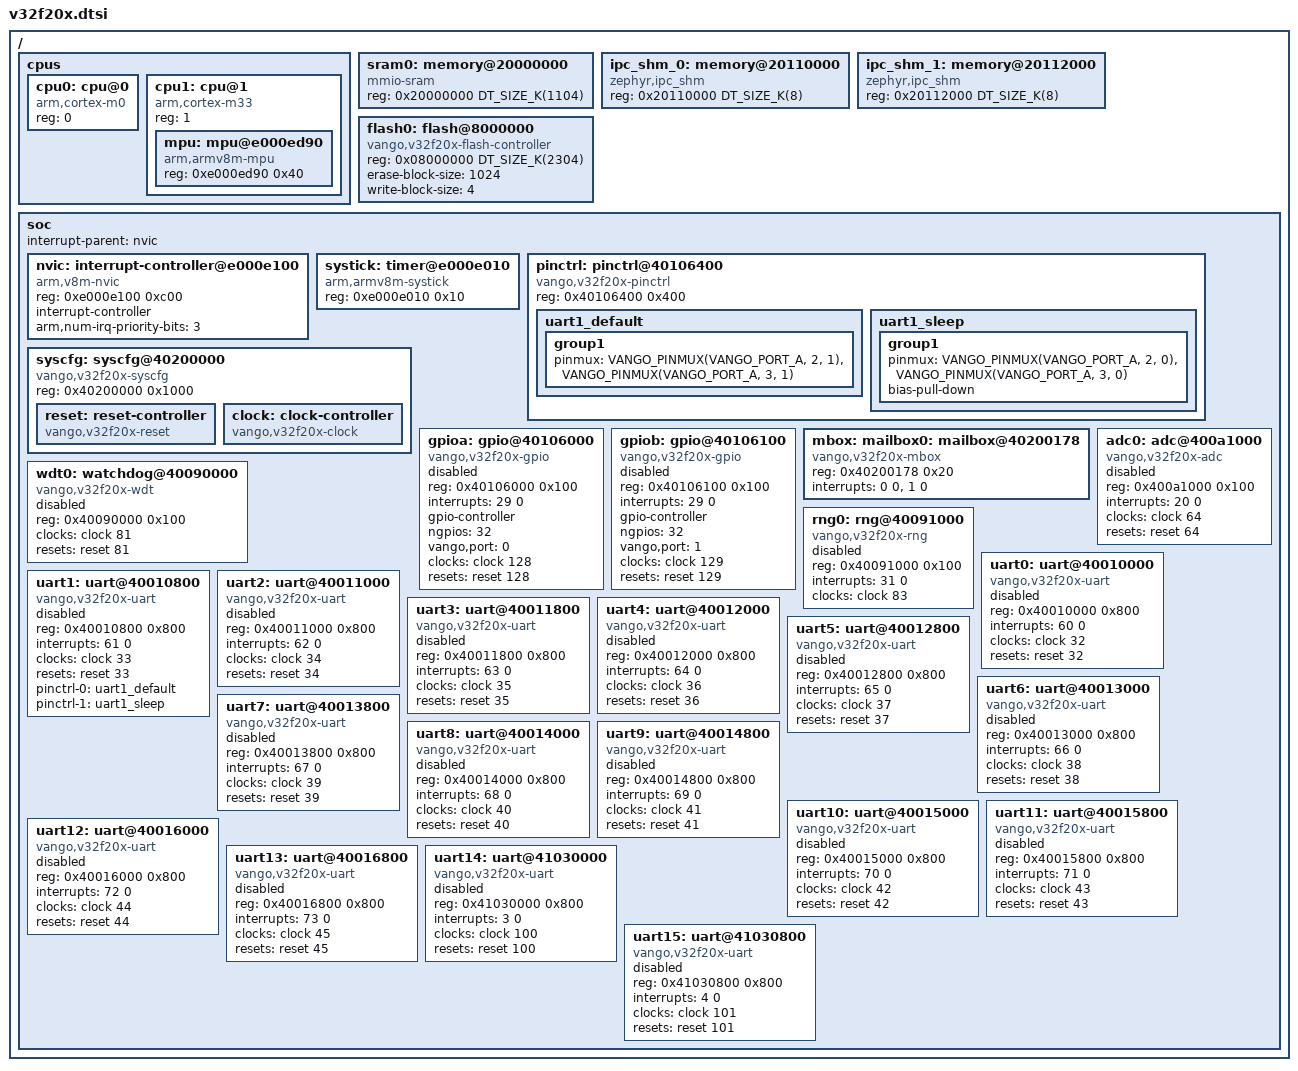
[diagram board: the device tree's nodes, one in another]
/*
 * Copyright (c) 2024 Vango Technologies
 * SPDX-License-Identifier: Apache-2.0
 */

#include <arm/armv8-m.dtsi>
#include <zephyr/dt-bindings/gpio/gpio.h>
#include <zephyr/dt-bindings/pinctrl/vango-v32f20x-pinctrl.h>
#include <mem.h>

/ {
    cpus {
        #address-cells = <1>;
        #size-cells = <0>;

        cpu0: cpu@0 {
            device_type = "cpu";
            compatible = "arm,cortex-m0";
            reg = <0>;
        };

        cpu1: cpu@1 {
            device_type = "cpu";
            compatible = "arm,cortex-m33";
            reg = <1>;
            #address-cells = <1>;
            #size-cells = <1>;

            mpu: mpu@e000ed90 {
                compatible = "arm,armv8m-mpu";
                reg = <0xe000ed90 0x40>;
            };
        };
    };

    sram0: memory@20000000 {
        compatible = "mmio-sram";
        reg = <0x20000000 DT_SIZE_K(1104)>;
    };

    ipc_shm_0: memory@20110000 {
        compatible = "zephyr,ipc_shm";
        reg = <0x20110000 DT_SIZE_K(8)>;
    };

    ipc_shm_1: memory@20112000 {
        compatible = "zephyr,ipc_shm";
        reg = <0x20112000 DT_SIZE_K(8)>;
    };

    flash0: flash@8000000 {
        compatible = "vango,v32f20x-flash-controller";
        reg = <0x08000000 DT_SIZE_K(2304)>;
        erase-block-size = <1024>;
        write-block-size = <4>;
    };

    soc: soc {
        #address-cells = <1>;
        #size-cells = <1>;
        ranges;
        interrupt-parent = <&nvic>;

        nvic: interrupt-controller@e000e100 {
            compatible = "arm,v8m-nvic";
            reg = <0xe000e100 0xc00>;
            interrupt-controller;
            #interrupt-cells = <2>;
            arm,num-irq-priority-bits = <3>;
        };

        systick: timer@e000e010 {
            status = "okay";
            compatible = "arm,armv8m-systick";
            reg = <0xe000e010 0x10>;
        };

        pinctrl: pinctrl@40106400 {
            compatible = "vango,v32f20x-pinctrl";
            reg = <0x40106400 0x400>;

            uart1_default: uart1_default {
                group1 {
                    pinmux = <VANGO_PINMUX(VANGO_PORT_A, 2, 1)>,
                             <VANGO_PINMUX(VANGO_PORT_A, 3, 1)>;
                };
            };
            uart1_sleep: uart1_sleep {
                group1 {
                    pinmux = <VANGO_PINMUX(VANGO_PORT_A, 2, 0)>,
                             <VANGO_PINMUX(VANGO_PORT_A, 3, 0)>;
                    bias-pull-down;
                };
            };
        };

        syscfg: syscfg@40200000 {
            compatible = "vango,v32f20x-syscfg", "syscon";
            reg = <0x40200000 0x1000>;

            reset: reset-controller {
                compatible = "vango,v32f20x-reset";
                #reset-cells = <1>;
            };

            clock: clock-controller {
                compatible = "vango,v32f20x-clock";
                #clock-cells = <1>;
            };
        };

        gpioa: gpio@40106000 {
            compatible = "vango,v32f20x-gpio";
            reg = <0x40106000 0x100>;
            interrupts = <29 0>;
            gpio-controller;
            #gpio-cells = <2>;
            ngpios = <32>;
            vango,port = <0>;
            clocks = <&clock 128>;
            resets = <&reset 128>;
            status = "disabled";
        };

        gpiob: gpio@40106100 {
            compatible = "vango,v32f20x-gpio";
            reg = <0x40106100 0x100>;
            interrupts = <29 0>;
            gpio-controller;
            #gpio-cells = <2>;
            ngpios = <32>;
            vango,port = <1>;
            clocks = <&clock 129>;
            resets = <&reset 129>;
            status = "disabled";
        };

        mbox: mailbox0: mailbox@40200178 {
            compatible = "vango,v32f20x-mbox";
            reg = <0x40200178 0x20>;
            interrupts = <0 0>, <1 0>;
            #mbox-cells = <1>;
            status = "okay";
        };

        wdt0: watchdog@40090000 {
            compatible = "vango,v32f20x-wdt";
            reg = <0x40090000 0x100>;
            clocks = <&clock 81>;
            resets = <&reset 81>;
            status = "disabled";
        };

        adc0: adc@400a1000 {
            compatible = "vango,v32f20x-adc";
            reg = <0x400a1000 0x100>;
            interrupts = <20 0>;
            clocks = <&clock 64>;
            resets = <&reset 64>;
            #io-channel-cells = <1>;
            status = "disabled";
        };

        rng0: rng@40091000 {
            compatible = "vango,v32f20x-rng";
            reg = <0x40091000 0x100>;
            interrupts = <31 0>;
            clocks = <&clock 83>;
            status = "disabled";
        };

        /* All SOC UARTs */
        uart0: uart@40010000 { compatible = "vango,v32f20x-uart"; reg = <0x40010000 0x800>; interrupts = <60 0>; clocks = <&clock 32>; resets = <&reset 32>; status = "disabled"; };
        uart1: uart@40010800 { compatible = "vango,v32f20x-uart"; reg = <0x40010800 0x800>; interrupts = <61 0>; clocks = <&clock 33>; resets = <&reset 33>; pinctrl-0 = <&uart1_default>; pinctrl-1 = <&uart1_sleep>; pinctrl-names = "default", "sleep"; status = "disabled"; };
        uart2: uart@40011000 { compatible = "vango,v32f20x-uart"; reg = <0x40011000 0x800>; interrupts = <62 0>; clocks = <&clock 34>; resets = <&reset 34>; status = "disabled"; };
        uart3: uart@40011800 { compatible = "vango,v32f20x-uart"; reg = <0x40011800 0x800>; interrupts = <63 0>; clocks = <&clock 35>; resets = <&reset 35>; status = "disabled"; };
        uart4: uart@40012000 { compatible = "vango,v32f20x-uart"; reg = <0x40012000 0x800>; interrupts = <64 0>; clocks = <&clock 36>; resets = <&reset 36>; status = "disabled"; };
        uart5: uart@40012800 { compatible = "vango,v32f20x-uart"; reg = <0x40012800 0x800>; interrupts = <65 0>; clocks = <&clock 37>; resets = <&reset 37>; status = "disabled"; };
        uart6: uart@40013000 { compatible = "vango,v32f20x-uart"; reg = <0x40013000 0x800>; interrupts = <66 0>; clocks = <&clock 38>; resets = <&reset 38>; status = "disabled"; };
        uart7: uart@40013800 { compatible = "vango,v32f20x-uart"; reg = <0x40013800 0x800>; interrupts = <67 0>; clocks = <&clock 39>; resets = <&reset 39>; status = "disabled"; };
        uart8: uart@40014000 { compatible = "vango,v32f20x-uart"; reg = <0x40014000 0x800>; interrupts = <68 0>; clocks = <&clock 40>; resets = <&reset 40>; status = "disabled"; };
        uart9: uart@40014800 { compatible = "vango,v32f20x-uart"; reg = <0x40014800 0x800>; interrupts = <69 0>; clocks = <&clock 41>; resets = <&reset 41>; status = "disabled"; };
        uart10: uart@40015000 { compatible = "vango,v32f20x-uart"; reg = <0x40015000 0x800>; interrupts = <70 0>; clocks = <&clock 42>; resets = <&reset 42>; status = "disabled"; };
        uart11: uart@40015800 { compatible = "vango,v32f20x-uart"; reg = <0x40015800 0x800>; interrupts = <71 0>; clocks = <&clock 43>; resets = <&reset 43>; status = "disabled"; };
        uart12: uart@40016000 { compatible = "vango,v32f20x-uart"; reg = <0x40016000 0x800>; interrupts = <72 0>; clocks = <&clock 44>; resets = <&reset 44>; status = "disabled"; };
        uart13: uart@40016800 { compatible = "vango,v32f20x-uart"; reg = <0x40016800 0x800>; interrupts = <73 0>; clocks = <&clock 45>; resets = <&reset 45>; status = "disabled"; };
        uart14: uart@41030000 { compatible = "vango,v32f20x-uart"; reg = <0x41030000 0x800>; interrupts = <3 0>; clocks = <&clock 100>; resets = <&reset 100>; status = "disabled"; };
        uart15: uart@41030800 { compatible = "vango,v32f20x-uart"; reg = <0x41030800 0x800>; interrupts = <4 0>; clocks = <&clock 101>; resets = <&reset 101>; status = "disabled"; };
    };
};
